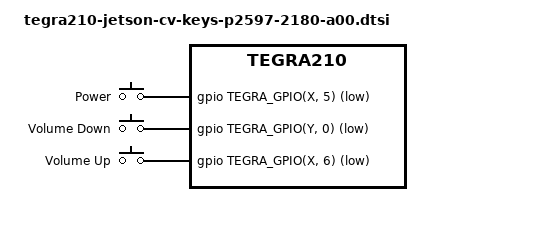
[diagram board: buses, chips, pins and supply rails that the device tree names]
/*
 * Copyright (c) 2015, NVIDIA CORPORATION.  All rights reserved.
 *
 * This program is free software; you can redistribute it and/or modify
 * it under the terms of the GNU General Public License as published by
 * the Free Software Foundation; version 2 of the License.
 *
 * This program is distributed in the hope that it will be useful, but WITHOUT
 * ANY WARRANTY; without even the implied warranty of MERCHANTABILITY or
 * FITNESS FOR A PARTICULAR PURPOSE.  See the GNU General Public License for
 * more details.
 *
 */
#include <dt-bindings/gpio/tegra-gpio.h>
#include <dt-bindings/input/input.h>

/ {
	gpio-keys {
		compatible = "gpio-keys";
		gpio-keys,name = "gpio-keys";
		power {
			label = "Power";
			gpios = <&gpio TEGRA_GPIO(X, 5) GPIO_ACTIVE_LOW>;
			linux,code = <KEY_POWER>;
			gpio-key,wakeup;
		};

		volume_down {
			label = "Volume Down";
			gpios = <&gpio TEGRA_GPIO(Y, 0) GPIO_ACTIVE_LOW>;
			linux,code = <KEY_VOLUMEDOWN>;
		};

		volume_up {
			label = "Volume Up";
			gpios = <&gpio TEGRA_GPIO(X, 6) GPIO_ACTIVE_LOW>;
			linux,code = <KEY_VOLUMEUP>;
		};
	};
};
